# PIC32MX420F032H register map
Vendor: Microchip
Registers are 32-bit, read-write, reset 0x0 unless marked. A register's access mark holds for its fields unless they carry their own. Addresses are absolute, and some are shared; only a register's first bit layout is shown; [hi:lo] are bit positions; {n}, {i} and the like mark numbered series.

## CMP1
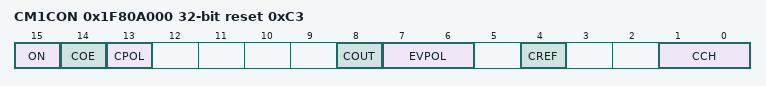
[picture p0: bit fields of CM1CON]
0x1F80A000 CM1CON reset 0xC3
  [15] ON, [14] COE, [13] CPOL, [8] COUT, [7:6] EVPOL, [4] CREF, [1:0] CCH

## CMP2
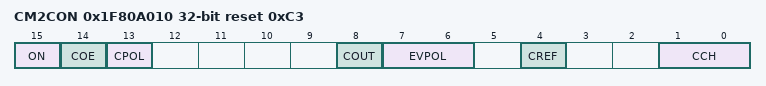
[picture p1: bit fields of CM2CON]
0x1F80A010 CM2CON reset 0xC3
  [15] ON, [14] COE, [13] CPOL, [8] COUT, [7:6] EVPOL, [4] CREF, [1:0] CCH

## cmp_control_pb
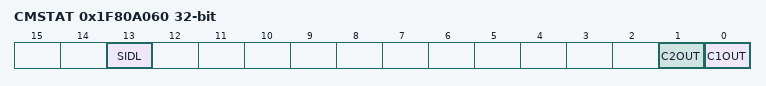
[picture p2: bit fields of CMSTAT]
0x1F80A060 CMSTAT
  [13] SIDL, [1] C2OUT ro, [0] C1OUT ro

## OSC
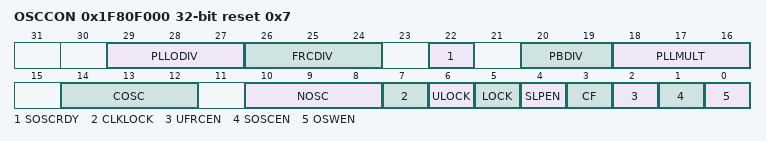
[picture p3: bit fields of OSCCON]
0x1F80F000 OSCCON reset 0x7
  [29:27] PLLODIV, [26:24] FRCDIV, [22] SOSCRDY, [20:19] PBDIV, [18:16] PLLMULT, [14:12] COSC, [10:8] NOSC, [7] CLKLOCK, [6] ULOCK, [5] LOCK, [4] SLPEN, [3] CF, [2] UFRCEN, [1] SOSCEN, [0] OSWEN
0x1F80F010 OSCTUN
  [5:0] TUN

## CFG
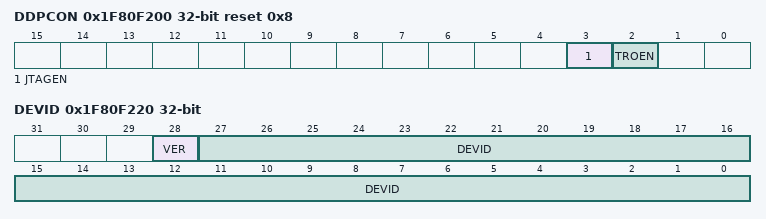
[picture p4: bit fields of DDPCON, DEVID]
0x1F80F200 DDPCON reset 0x8
  [3] JTAGEN, [2] TROEN
0x1F80F220 DEVID ro reset not defined — (power-on value xxxxxxxxxxxxxxxxxxxxxxxxxxxxxxxx)
  [28] VER, [27:0] DEVID
0x1F80F230 SYSKEY ro reset not defined — (power-on value xxxxxxxxxxxxxxxxxxxxxxxxxxxxxxxx)

## NVM
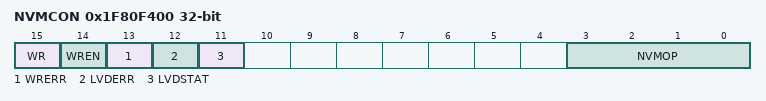
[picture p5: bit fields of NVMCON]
0x1F80F400 NVMCON
  [15] WR, [14] WREN, [13] WRERR ro, [12] LVDERR ro, [11] LVDSTAT ro, [3:0] NVMOP
0x1F80F410 NVMKEY wo
0x1F80F420 NVMADDR
0x1F80F430 NVMDATA
0x1F80F440 NVMSRCADDR

## RCON
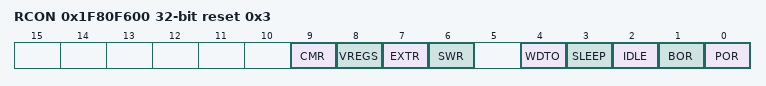
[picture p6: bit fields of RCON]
0x1F80F600 RCON reset 0x3
  [9] CMR, [8] VREGS, [7] EXTR, [6] SWR, [4] WDTO, [3] SLEEP, [2] IDLE, [1] BOR, [0] POR
0x1F80F610 RSWRST
  [0] SWRST

## _DDPSTAT
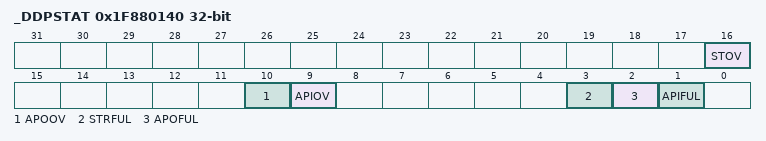
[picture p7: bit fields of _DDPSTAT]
0x1F880140 _DDPSTAT
  [16] STOV, [10] APOOV, [9] APIOV, [3] STRFUL, [2] APOFUL, [1] APIFUL

## _STRO
0x1F880170 _STRO reset not defined — George (power-on value xxxxxxxxxxxxxxxxxxxxxxxxxxxxxxxx)

## _APPO
0x1F880180 _APPO reset not defined — George (power-on value xxxxxxxxxxxxxxxxxxxxxxxxxxxxxxxx)

## _APPI
0x1F880190 _APPI reset not defined — George (power-on value xxxxxxxxxxxxxxxxxxxxxxxxxxxxxxxx)

## INT
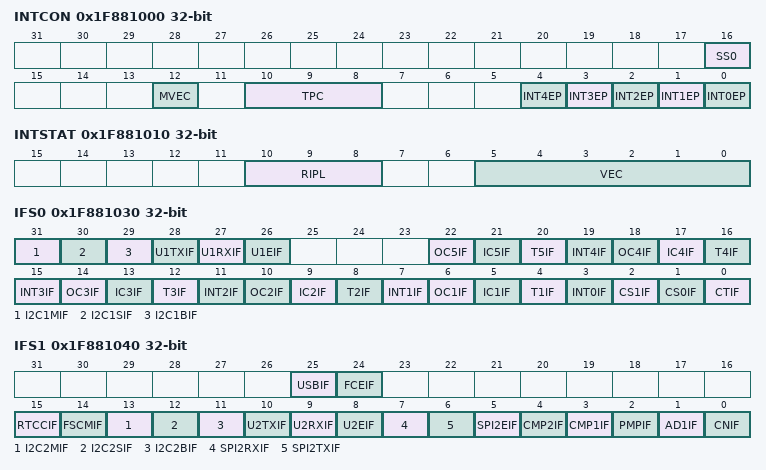
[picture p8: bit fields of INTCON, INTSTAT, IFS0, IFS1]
0x1F881000 INTCON
  [16] SS0, [12] MVEC, [10:8] TPC, [n] INT{n}EP (n=0..4)
0x1F881010 INTSTAT
  [10:8] RIPL, [5:0] VEC
0x1F881020 IPTMR
0x1F881030 IFS0
  [31] I2C1MIF, [30] I2C1SIF, [29] I2C1BIF, [28] U1TXIF, [27] U1RXIF, [26] U1EIF, [4n+2] OC{n}IF (n=1..5), [4n+1] IC{n}IF (n=1..5), [4n] T{n}IF (n=1..5), [4n+3] INT{n}IF (n=0..4), [2] CS1IF, [1] CS0IF, [0] CTIF
0x1F881040 IFS1
  [25] USBIF, [24] FCEIF, [15] RTCCIF, [14] FSCMIF, [13] I2C2MIF, [12] I2C2SIF, [11] I2C2BIF, [10] U2TXIF, [9] U2RXIF, [8] U2EIF, [7] SPI2RXIF, [6] SPI2TXIF, [5] SPI2EIF, [4] CMP2IF, [3] CMP1IF, [2] PMPIF, [1] AD1IF, [0] CNIF
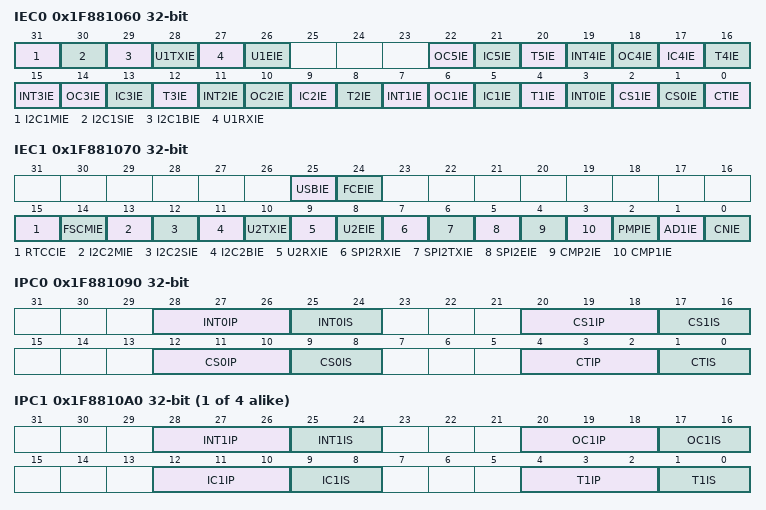
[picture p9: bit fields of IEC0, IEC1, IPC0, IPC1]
0x1F881060 IEC0
  [31] I2C1MIE, [30] I2C1SIE, [29] I2C1BIE, [28] U1TXIE, [27] U1RXIE, [26] U1EIE, [4n+2] OC{n}IE (n=1..5), [4n+1] IC{n}IE (n=1..5), [4n] T{n}IE (n=1..5), [4n+3] INT{n}IE (n=0..4), [2] CS1IE, [1] CS0IE, [0] CTIE
0x1F881070 IEC1
  [25] USBIE, [24] FCEIE, [15] RTCCIE, [14] FSCMIE, [13] I2C2MIE, [12] I2C2SIE, [11] I2C2BIE, [10] U2TXIE, [9] U2RXIE, [8] U2EIE, [7] SPI2RXIE, [6] SPI2TXIE, [5] SPI2EIE, [4] CMP2IE, [3] CMP1IE, [2] PMPIE, [1] AD1IE, [0] CNIE
0x1F881090 IPC0
  [28:26] INT0IP, [25:24] INT0IS, [20:18] CS1IP, [17:16] CS1IS, [12:10] CS0IP, [9:8] CS0IS, [4:2] CTIP, [1:0] CTIS
{0x1F881090+0x10*i} IPC{i} (i=1..4)
  [28:26] INT{i}IP, [25:24] INT{i}IS, [20:18] OC{i}IP, [17:16] OC{i}IS, [12:10] IC{i}IP, [9:8] IC{i}IS, [4:2] T{i}IP, [1:0] T{i}IS
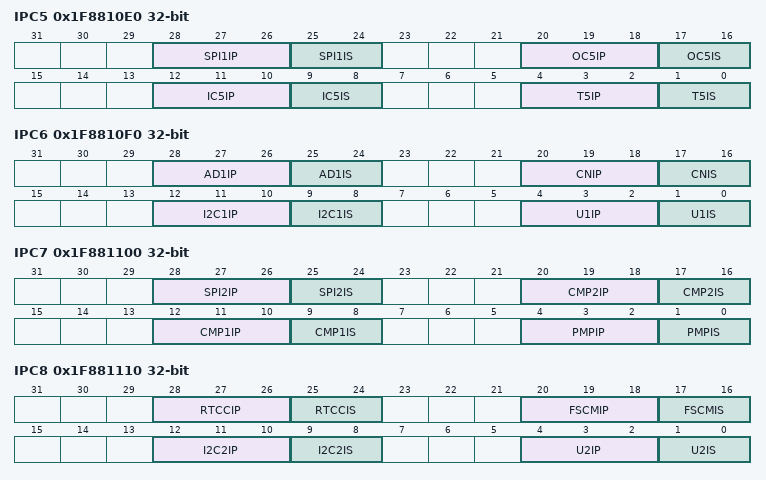
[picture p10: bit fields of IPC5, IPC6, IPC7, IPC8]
0x1F8810E0 IPC5
  [28:26] SPI1IP, [25:24] SPI1IS, [20:18] OC5IP, [17:16] OC5IS, [12:10] IC5IP, [9:8] IC5IS, [4:2] T5IP, [1:0] T5IS
0x1F8810F0 IPC6
  [28:26] AD1IP, [25:24] AD1IS, [20:18] CNIP, [17:16] CNIS, [12:10] I2C1IP, [9:8] I2C1IS, [4:2] U1IP, [1:0] U1IS
0x1F881100 IPC7
  [28:26] SPI2IP, [25:24] SPI2IS, [20:18] CMP2IP, [17:16] CMP2IS, [12:10] CMP1IP, [9:8] CMP1IS, [4:2] PMPIP, [1:0] PMPIS
0x1F881110 IPC8
  [28:26] RTCCIP, [25:24] RTCCIS, [20:18] FSCMIP, [17:16] FSCMIS, [12:10] I2C2IP, [9:8] I2C2IS, [4:2] U2IP, [1:0] U2IS
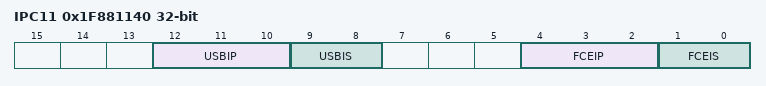
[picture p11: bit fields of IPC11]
0x1F881140 IPC11
  [12:10] USBIP, [9:8] USBIS, [4:2] FCEIP, [1:0] FCEIS
